# GD32E53x register map
File version: 1.0
CPU: CM33 r0p4, little endian, MPU, FPU, 4 interrupt priority bits
Registers are 32-bit, read-write, reset 0x0 unless marked. A register's access mark holds for its fields unless they carry their own. Offsets are from the block's base; [hi:lo] are bit positions.

## USART5 — Universal synchronous / asynchronous receiver / transmitter
Base 0x40017000
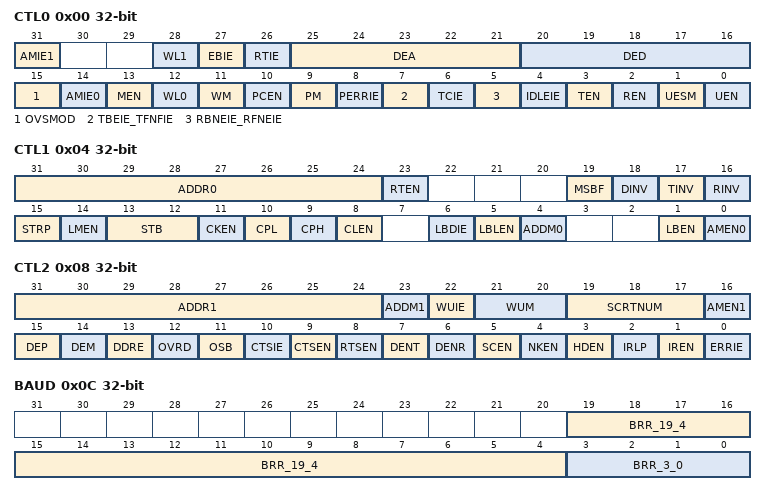
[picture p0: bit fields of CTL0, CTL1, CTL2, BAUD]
0x00 CTL0 — Control register 0
  [31] AMIE1 — ADDR1 character match interrupt enable
  [28] WL1 — Word length 1
  [27] EBIE — End of block interrupt enable
  [26] RTIE — Receiver timeout interrupt enable
  [25:21] DEA — Driver enable assertion time
  [20:16] DED — Driver enable de-assertion time
  [15] OVSMOD — Oversample mode
  [14] AMIE0 — ADDR0 character match interrupt enable
  [13] MEN — Mute mode enable
  [12] WL0 — Word length 0
  [11] WM — Wakeup method in mute mode
  [10] PCEN — Parity control enable
  [9] PM — Parity mode
  [8] PERRIE — Parity error interrupt enable
  [7] TBEIE_TFNFIE — When FIFO is disabled:
  [6] TCIE — Transmission complete interrupt enable
  [5] RBNEIE_RFNEIE — When FIFO is disabled:
  [4] IDLEIE — IDLE line detected interrupt enable
  [3] TEN — Transmitter enable
  [2] REN — Receiver enable
  [1] UESM — USART enable in Deep-sleep mode
  [0] UEN — USART enable
0x04 CTL1 — Control register 1
  [31:24] ADDR0 — Address 0 of the USART terminal
  [23] RTEN — Receiver timeout enable
  [19] MSBF — Most significant bit first
  [18] DINV — Data bit level inversion
  [17] TINV — TX pin level inversion
  [16] RINV — RX pin level inversion
  [15] STRP — Swap TX / RX pins
  [14] LMEN — LIN mode enable
  [13:12] STB — STOP bits length
  [11] CKEN — CK pin enable
  [10] CPL — Clock polarity
  [9] CPH — Clock phase
  [8] CLEN — CK length
  [6] LBDIE — LIN break detection interrupt enable
  [5] LBLEN — LIN break frame length
  [4] ADDM0 — Address 0 detection mode
  [1] LBEN — Loopback mode
  [0] AMEN0 — Address 0 match mode enable
0x08 CTL2 — Control register 2
  [31:24] ADDR1 — Address 1 of the USART terminal
  [23] ADDM1 — Address 1 detection mode
  [22] WUIE — Wakeup from deep-sleep mode interrupt enable
  [21:20] WUM — Wakeup mode from deep-sleep mode
  [19:17] SCRTNUM — Smartcard auto-retry number
  [16] AMEN1 — Address 1 match mode enable
  [15] DEP — Driver enable polarity mode
  [14] DEM — Driver enable mode
  [13] DDRE — Mask DMA request on reception error.
  [12] OVRD — Overrun disable
  [11] OSB — One sample bit method
  [10] CTSIE — CTS interrupt enable
  [9] CTSEN — CTS enable
  [8] RTSEN — RTS enable
  [7] DENT — DMA enable for transmission
  [6] DENR — DMA enable for reception
  [5] SCEN — Smartcard mode enable
  [4] NKEN — NACK enable in Smartcard mode
  [3] HDEN — Half-duplex enable
  [2] IRLP — IrDA low-power
  [1] IREN — IrDA mode enable
  [0] ERRIE — Error interrupt enable
0x0C BAUD — Baud rate generator register
  [19:4] BRR_19_4 — Integer of baud-rate divider
  [3:0] BRR_3_0 — Fraction of baud-rate divider
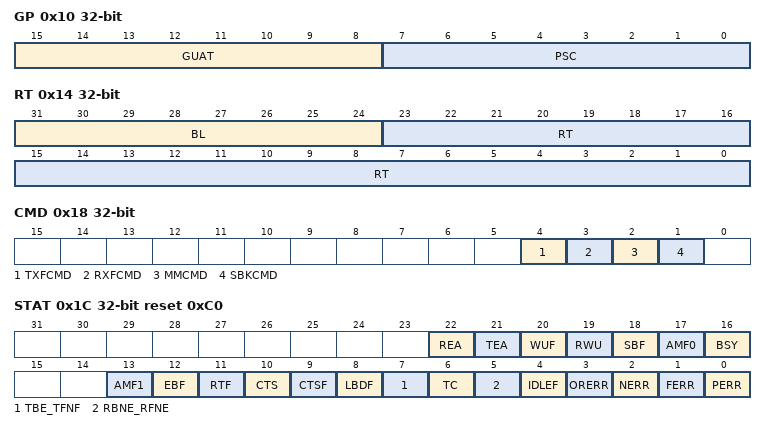
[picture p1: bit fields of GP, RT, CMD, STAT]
0x10 GP — Prescaler and guard time configuration register
  [15:8] GUAT — Guard time value in smartcard mode.
  [7:0] PSC — Prescaler value for dividing the system clock.
0x14 RT — Receiver timeout register
  [31:24] BL — Block Length.
  [23:0] RT — Receiver timeout threshold.
0x18 CMD wo — Command register
  [4] TXFCMD — Transmit data flush request
  [3] RXFCMD — Receive data flush command
  [2] MMCMD — Mute mode command
  [1] SBKCMD — Send break command
0x1C STAT ro reset 0xC0 — Status register
  [22] REA — Receive enable acknowledge flag
  [21] TEA — Transmit enable acknowledge flag
  [20] WUF — Wakeup from deep-sleep mode and deep-sleep 1 flag
  [19] RWU — Receiver wakeup from mute mode
  [18] SBF — Send break flag
  [17] AMF0 — ADDR0 character match flag
  [16] BSY — Busy flag
  [13] AMF1 — ADDR1 character match flag
  [12] EBF — End of block flag
  [11] RTF — Receiver timeout flag
  [10] CTS — CTS level
  [9] CTSF — CTS change flag
  [8] LBDF — LIN break detected flag
  [7] TBE_TFNF — When FIFO is disabled:
  [6] TC — Transmission completed
  [5] RBNE_RFNE — When FIFO is disabled:
  [4] IDLEF — IDLE line detected flag
  [3] ORERR — Overrun error
  [2] NERR — Noise error flag
  [1] FERR — Frame error flag
  [0] PERR — Parity error flag
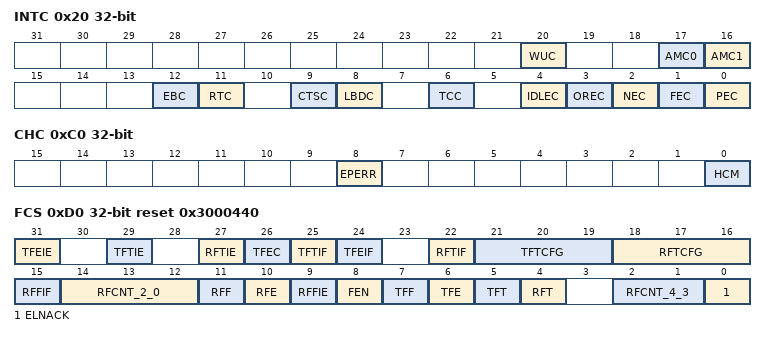
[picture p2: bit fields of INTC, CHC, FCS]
0x20 INTC wo — Interrupt status clear register
  [20] WUC — Wakeup from deep-sleep mode clear
  [17] AMC0 — ADDR0 character match clear
  [16] AMC1 — ADDR1 character match clear
  [12] EBC — End of block clear
  [11] RTC — Receiver timeout clear
  [9] CTSC — CTS change clear
  [8] LBDC — LIN break detected clear
  [6] TCC — Transmission complete clear
  [4] IDLEC — Idle line detected clear
  [3] OREC — Overrun error clear
  [2] NEC — Noise detected clear
  [1] FEC — Frame error flag clear
  [0] PEC — Parity error clear
0x24 RDATA ro — Receive data register
  [8:0] RDATA — Receive data value
0x28 TDATA — Transmit data register
  [9:0] TDATA — Transmit Data value
0xC0 CHC — USART coherence control register
  [8] EPERR — Early parity error flag. This flag will be set as soon as the parity bit has been detected, which is before RBNE flag. This flag is cleared by writing 0.
  [0] HCM — Hardware flow control coherence mode
0xD0 FCS access per field reset 0x3000440 — USART FIFO control and status register
  [31] TFEIE rw — Transmit FIFO empty interrupt enable
  [29] TFTIE rw — Transmit FIFO threshold interrupt enable
  [27] RFTIE rw — Receive FIFO threshold interrupt enable
  [26] TFEC rw — Transmit FIFO empty flag clear
  [25] TFTIF ro — Transmit FIFO threshold interrupt flag
  [24] TFEIF ro — Transmit FIFO empty interrupt flag
  [22] RFTIF rw — Receive FIFO threshold interrupt flag
  [21:19] TFTCFG rw — Transmit FIFO threshold configuration
  [18:16] RFTCFG rw — Receive FIFO threshold configuration
  [15] RFFIF rw — Receive FIFO full interrupt flag
  [14:12] RFCNT_2_0 ro — Receive FIFO counter number
  [11] RFF ro — Receive FIFO full flag
  [10] RFE ro — Receive FIFO empty flag
  [9] RFFIE rw — Receive FIFO full interrupt enable
  [8] FEN rw — FIFO enable
  [7] TFF ro — Transmit FIFO full flag
  [6] TFE ro — Transmit FIFO empty flag
  [5] TFT ro — Transmit FIFO threshold flag
  [4] RFT ro — Receive FIFO threshold flag
  [2:1] RFCNT_4_3 ro — Receive FIFO counter number
  [0] ELNACK rw — Early NACK when smartcard mode is selected.
